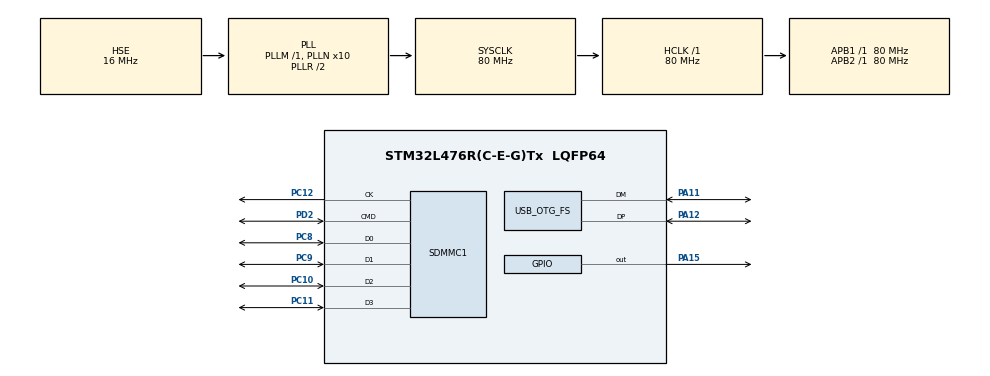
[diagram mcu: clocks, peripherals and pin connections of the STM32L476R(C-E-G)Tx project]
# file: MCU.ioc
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Dma.Request0=SDMMC1
Dma.SDMMC1.0.Direction=DMA_MEMORY_TO_PERIPH
Dma.SDMMC1.0.Instance=DMA2_Channel4
Dma.SDMMC1.0.MemDataAlignment=DMA_MDATAALIGN_WORD
Dma.SDMMC1.0.MemInc=DMA_MINC_ENABLE
Dma.SDMMC1.0.Mode=DMA_NORMAL
Dma.SDMMC1.0.PeriphDataAlignment=DMA_PDATAALIGN_WORD
Dma.SDMMC1.0.PeriphInc=DMA_PINC_DISABLE
Dma.SDMMC1.0.Priority=DMA_PRIORITY_LOW
Mcu.Family=STM32L4
Mcu.Name=STM32L476R(C-E-G)Tx
Mcu.Package=LQFP64
NVIC.DMA2_Channel4_IRQn=true\:0\:0\:true\:false\:true\:false\:true\:true
NVIC.OTG_FS_IRQn=true\:2\:0\:true\:false\:true\:false\:true\:true
NVIC.PriorityGroup=NVIC_PRIORITYGROUP_4
NVIC.SDMMC1_IRQn=true\:1\:0\:true\:false\:true\:true\:true\:true
NVIC.TIM1_BRK_TIM15_IRQn=true\:15\:0\:false\:false\:true\:false\:true\:true
NVIC.TimeBase=TIM1_BRK_TIM15_IRQn
NVIC.TimeBaseIP=TIM15
PA11.Mode=Device_Only
PA11.Signal=USB_OTG_FS_DM
PA12.Mode=Device_Only
PA12.Signal=USB_OTG_FS_DP
PA13\ (JTMS-SWDIO).Mode=Serial_Wire
PA13\ (JTMS-SWDIO).Signal=SYS_JTMS-SWDIO
PA14\ (JTCK-SWCLK).Mode=Serial_Wire
PA14\ (JTCK-SWCLK).Signal=SYS_JTCK-SWCLK
PA15\ (JTDI).Signal=GPIO_Output
PC10.Mode=mmc_4_bits_Wide_bus
PC10.Signal=SDMMC1_D2
PC11.Mode=mmc_4_bits_Wide_bus
PC11.Signal=SDMMC1_D3
PC12.Mode=mmc_4_bits_Wide_bus
PC12.Signal=SDMMC1_CK
PC8.Mode=mmc_4_bits_Wide_bus
PC8.Signal=SDMMC1_D0
PC9.Mode=mmc_4_bits_Wide_bus
PC9.Signal=SDMMC1_D1
PD2.Mode=mmc_4_bits_Wide_bus
PD2.Signal=SDMMC1_CMD
PH0-OSC_IN\ (PH0).Mode=HSE-External-Oscillator
PH0-OSC_IN\ (PH0).Signal=RCC_OSC_IN
PH1-OSC_OUT\ (PH1).Mode=HSE-External-Oscillator
PH1-OSC_OUT\ (PH1).Signal=RCC_OSC_OUT
ProjectManager.HeapSize=0x3000
ProjectManager.StackSize=0x2000
ProjectManager.TargetToolchain=STM32CubeIDE
RCC.ADCFreq_Value=96000000
RCC.AHBFreq_Value=80000000
RCC.APB1Freq_Value=80000000
RCC.APB1TimFreq_Value=80000000
RCC.APB2Freq_Value=80000000
RCC.APB2TimFreq_Value=80000000
RCC.CortexFreq_Value=80000000
RCC.HCLKFreq_Value=80000000
RCC.HSE_VALUE=16000000
RCC.HSI_VALUE=16000000
RCC.LSE_VALUE=32768
RCC.MSIClockRange=RCC_MSIRANGE_9
RCC.MSI_VALUE=24000000
RCC.PLLN=10
RCC.PLLQ=RCC_PLLQ_DIV4
RCC.PLLSAI1N=12
RCC.PLLSAI1Q=RCC_PLLQ_DIV4
RCC.PLLSourceVirtual=RCC_PLLSOURCE_HSE
RCC.SYSCLKFreq_VALUE=80000000
RCC.SYSCLKSource=RCC_SYSCLKSOURCE_PLLCLK
RCC.USBFreq_Value=48000000
RCC.VCOOutputFreq_Value=160000000
SDMMC1.ClockDiv=0
SDMMC1.ClockPowerSave=SDMMC_CLOCK_POWER_SAVE_ENABLE
SDMMC1.HardwareFlowControl=SDMMC_HARDWARE_FLOW_CONTROL_ENABLE
USB_DEVICE.CLASS_NAME_FS=MSC
USB_DEVICE.MSC_MEDIA_PACKET=32768
USB_DEVICE.VirtualMode=Msc
USB_DEVICE.VirtualModeFS=Msc_FS
USB_OTG_FS.VirtualMode=Device_Only
VP_CRC_VS_CRC.Mode=CRC_Activate
VP_SYS_VS_tim15.Mode=TIM15
VP_SYS_V_PVD_IN.Mode=Mode_PVD_Int
VP_USB_DEVICE_VS_USB_DEVICE_MSC_FS.Mode=MSC_FS
board=custom

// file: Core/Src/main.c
/* USER CODE BEGIN Header */
/**
 ******************************************************************************
 * @file           : main.c
 * @brief          : Main program body
 ******************************************************************************
 * @attention
 *
 * Copyright (c) 2024 STMicroelectronics.
 * All rights reserved.
 *
 * This software is licensed under terms that can be found in the LICENSE file
 * in the root directory of this software component.
 * If no LICENSE file comes with this software, it is provided AS-IS.
 *
 ******************************************************************************
 */
/* USER CODE END Header */
#include "main.h"
#include "usb_device.h"

CRC_HandleTypeDef hcrc;

MMC_HandleTypeDef hmmc1;
DMA_HandleTypeDef hdma_sdmmc1;

void SystemClock_Config(void);
void PeriphCommonClock_Config(void);
static void MX_GPIO_Init(void);
static void MX_DMA_Init(void);
static void MX_SDMMC1_MMC_Init(void);
static void MX_CRC_Init(void);

/* USER CODE BEGIN 0 */

void HAL_MMC_ErrorCallback(MMC_HandleTypeDef *hmmc)
{
  __BKPT();
}
void HAL_MMC_AbortCallback(MMC_HandleTypeDef *hmmc)
{
  __BKPT();
}
/* USER CODE END 0 */

int main(void)
{

  /* MCU Configuration--------------------------------------------------------*/

  /* Reset of all peripherals, Initializes the Flash interface and the Systick. */
  HAL_Init();

  /* Configure the system clock */
  SystemClock_Config();

/* Configure the peripherals common clocks */
  PeriphCommonClock_Config();

  /* Initialize all configured peripherals */
  MX_GPIO_Init();
  MX_DMA_Init();
  MX_SDMMC1_MMC_Init();
  MX_USB_DEVICE_Init();
  MX_CRC_Init();
  /* USER CODE BEGIN 2 */

  // 3 CASES7
  // 1. SYSTEM IS CONNECTED AS TELEMETRY GROUND STATION
  // 2. SYSTEM IS CONNECTED TO A COMPUTER AS A USB MASS STORAGE CLASS DEVICE
  // 3. SYSTEM IS LOGGING INFORMATION TO THE eMMC
  // TODO: WAIT FOR USER INPUT TO DECIDE WHETHER TO CHOOSE CASE 1 OR 2, IF TIMEOUT AFTER 60 SECONDS ACT AS LOGGING DEVICE.
  // OR TODO: USE USB COMPOSITE DEVICE

  // CURRENT CONFIGURATION - ONLY USE AS MASS STORAGE DEVICE.2

  // CHECK IF USB IS CONNECTED AND DISABLE FATFS IF CONNECTED.

  /* USER CODE END 2 */

  /* Infinite loop */
  while (1)
  {

  }
}

void SystemClock_Config(void)
{
  RCC_OscInitTypeDef RCC_OscInitStruct = {0};
  RCC_ClkInitTypeDef RCC_ClkInitStruct = {0};

  /** Configure the main internal regulator output voltage
  */
  if (HAL_PWREx_ControlVoltageScaling(PWR_REGULATOR_VOLTAGE_SCALE1) != HAL_OK)
  {
    Error_Handler();
  }

  /** Initializes the RCC Oscillators according to the specified parameters
  * in the RCC_OscInitTypeDef structure.
  */
  RCC_OscInitStruct.OscillatorType = RCC_OSCILLATORTYPE_HSE;
  RCC_OscInitStruct.HSEState = RCC_HSE_ON;
  RCC_OscInitStruct.PLL.PLLState = RCC_PLL_ON;
  RCC_OscInitStruct.PLL.PLLSource = RCC_PLLSOURCE_HSE;
  RCC_OscInitStruct.PLL.PLLM = 1;
  RCC_OscInitStruct.PLL.PLLN = 10;
  RCC_OscInitStruct.PLL.PLLP = RCC_PLLP_DIV7;
  RCC_OscInitStruct.PLL.PLLQ = RCC_PLLQ_DIV4;
  RCC_OscInitStruct.PLL.PLLR = RCC_PLLR_DIV2;
  if (HAL_RCC_OscConfig(&RCC_OscInitStruct) != HAL_OK)
  {
    Error_Handler();
  }

  /** Initializes the CPU, AHB and APB buses clocks
  */
  RCC_ClkInitStruct.ClockType = RCC_CLOCKTYPE_HCLK|RCC_CLOCKTYPE_SYSCLK
                              |RCC_CLOCKTYPE_PCLK1|RCC_CLOCKTYPE_PCLK2;
  RCC_ClkInitStruct.SYSCLKSource = RCC_SYSCLKSOURCE_PLLCLK;
  RCC_ClkInitStruct.AHBCLKDivider = RCC_SYSCLK_DIV1;
  RCC_ClkInitStruct.APB1CLKDivider = RCC_HCLK_DIV1;
  RCC_ClkInitStruct.APB2CLKDivider = RCC_HCLK_DIV1;

  if (HAL_RCC_ClockConfig(&RCC_ClkInitStruct, FLASH_LATENCY_4) != HAL_OK)
  {
    Error_Handler();
  }
}

void PeriphCommonClock_Config(void)
{
  RCC_PeriphCLKInitTypeDef PeriphClkInit = {0};

  /** Initializes the peripherals clock
  */
  PeriphClkInit.PeriphClockSelection = RCC_PERIPHCLK_USB|RCC_PERIPHCLK_SDMMC1;
  PeriphClkInit.UsbClockSelection = RCC_USBCLKSOURCE_PLLSAI1;
  PeriphClkInit.Sdmmc1ClockSelection = RCC_SDMMC1CLKSOURCE_PLLSAI1;
  PeriphClkInit.PLLSAI1.PLLSAI1Source = RCC_PLLSOURCE_HSE;
  PeriphClkInit.PLLSAI1.PLLSAI1M = 1;
  PeriphClkInit.PLLSAI1.PLLSAI1N = 12;
  PeriphClkInit.PLLSAI1.PLLSAI1P = RCC_PLLP_DIV7;
  PeriphClkInit.PLLSAI1.PLLSAI1Q = RCC_PLLQ_DIV4;
  PeriphClkInit.PLLSAI1.PLLSAI1R = RCC_PLLR_DIV2;
  PeriphClkInit.PLLSAI1.PLLSAI1ClockOut = RCC_PLLSAI1_48M2CLK;
  if (HAL_RCCEx_PeriphCLKConfig(&PeriphClkInit) != HAL_OK)
  {
    Error_Handler();
  }
}

static void MX_CRC_Init(void)
{

  hcrc.Instance = CRC;
  hcrc.Init.DefaultPolynomialUse = DEFAULT_POLYNOMIAL_ENABLE;
  hcrc.Init.DefaultInitValueUse = DEFAULT_INIT_VALUE_ENABLE;
  hcrc.Init.InputDataInversionMode = CRC_INPUTDATA_INVERSION_NONE;
  hcrc.Init.OutputDataInversionMode = CRC_OUTPUTDATA_INVERSION_DISABLE;
  hcrc.InputDataFormat = CRC_INPUTDATA_FORMAT_BYTES;
  if (HAL_CRC_Init(&hcrc) != HAL_OK)
  {
    Error_Handler();
  }

}

static void MX_SDMMC1_MMC_Init(void)
{

  hmmc1.Instance = SDMMC1;
  hmmc1.Init.ClockEdge = SDMMC_CLOCK_EDGE_RISING;
  hmmc1.Init.ClockBypass = SDMMC_CLOCK_BYPASS_DISABLE;
  hmmc1.Init.ClockPowerSave = SDMMC_CLOCK_POWER_SAVE_ENABLE;
  hmmc1.Init.BusWide = SDMMC_BUS_WIDE_4B;
  hmmc1.Init.HardwareFlowControl = SDMMC_HARDWARE_FLOW_CONTROL_ENABLE;
  hmmc1.Init.ClockDiv = 0;
  if (HAL_MMC_Init(&hmmc1) != HAL_OK)
  {
    Error_Handler();
  }
  if (HAL_MMC_ConfigWideBusOperation(&hmmc1, SDMMC_BUS_WIDE_4B) != HAL_OK)
  {
    Error_Handler();
  }

}

static void MX_DMA_Init(void)
{

  /* DMA controller clock enable */
  __HAL_RCC_DMA2_CLK_ENABLE();

  /* DMA interrupt init */
  /* DMA2_Channel4_IRQn interrupt configuration */
  HAL_NVIC_SetPriority(DMA2_Channel4_IRQn, 0, 0);
  HAL_NVIC_EnableIRQ(DMA2_Channel4_IRQn);

}

static void MX_GPIO_Init(void)
{
  GPIO_InitTypeDef GPIO_InitStruct = {0};

  /* GPIO Ports Clock Enable */
  __HAL_RCC_GPIOH_CLK_ENABLE();
  __HAL_RCC_GPIOC_CLK_ENABLE();
  __HAL_RCC_GPIOA_CLK_ENABLE();
  __HAL_RCC_GPIOD_CLK_ENABLE();

  /*Configure GPIO pin Output Level */
  HAL_GPIO_WritePin(GPIOA, GPIO_PIN_15, GPIO_PIN_RESET);

  /*Configure GPIO pin : PA15 */
  GPIO_InitStruct.Pin = GPIO_PIN_15;
  GPIO_InitStruct.Mode = GPIO_MODE_OUTPUT_PP;
  GPIO_InitStruct.Pull = GPIO_NOPULL;
  GPIO_InitStruct.Speed = GPIO_SPEED_FREQ_LOW;
  HAL_GPIO_Init(GPIOA, &GPIO_InitStruct);

}

void HAL_TIM_PeriodElapsedCallback(TIM_HandleTypeDef *htim)
{
  if (htim->Instance == TIM15) {
    HAL_IncTick();
  }
}

void Error_Handler(void)
{
  __disable_irq();
  while (1)
  {
  }
}
